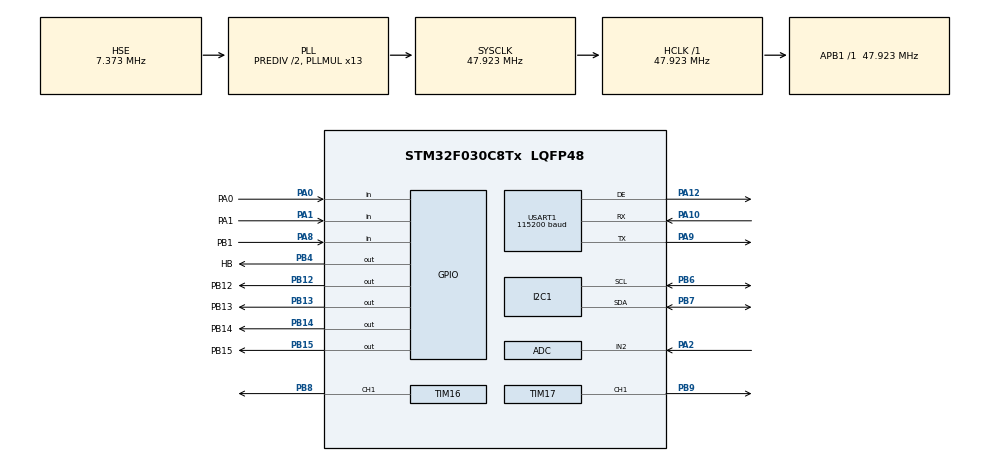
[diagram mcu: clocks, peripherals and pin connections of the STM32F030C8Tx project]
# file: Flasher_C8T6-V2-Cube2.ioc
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ADC.DMAContinuousRequests=ENABLE
ADC.EOCSelection=ADC_EOC_SEQ_CONV
ADC.ExternalTrigConv=ADC_EXTERNALTRIGCONV_T15_TRGO
ADC.SamplingTime=ADC_SAMPLETIME_13CYCLES_5
CRC.DefaultInitValueUse=DEFAULT_INIT_VALUE_ENABLE
Dma.ADC.4.Direction=DMA_PERIPH_TO_MEMORY
Dma.ADC.4.Instance=DMA1_Channel1
Dma.ADC.4.MemDataAlignment=DMA_MDATAALIGN_HALFWORD
Dma.ADC.4.MemInc=DMA_MINC_ENABLE
Dma.ADC.4.Mode=DMA_NORMAL
Dma.ADC.4.PeriphDataAlignment=DMA_PDATAALIGN_HALFWORD
Dma.ADC.4.PeriphInc=DMA_PINC_DISABLE
Dma.ADC.4.Priority=DMA_PRIORITY_LOW
Dma.I2C1_RX.0.Direction=DMA_PERIPH_TO_MEMORY
Dma.I2C1_RX.0.Instance=DMA1_Channel3
Dma.I2C1_RX.0.MemDataAlignment=DMA_MDATAALIGN_BYTE
Dma.I2C1_RX.0.MemInc=DMA_MINC_ENABLE
Dma.I2C1_RX.0.Mode=DMA_NORMAL
Dma.I2C1_RX.0.PeriphDataAlignment=DMA_PDATAALIGN_BYTE
Dma.I2C1_RX.0.PeriphInc=DMA_PINC_DISABLE
Dma.I2C1_RX.0.Priority=DMA_PRIORITY_LOW
Dma.I2C1_TX.1.Direction=DMA_MEMORY_TO_PERIPH
Dma.I2C1_TX.1.Instance=DMA1_Channel2
Dma.I2C1_TX.1.MemDataAlignment=DMA_MDATAALIGN_BYTE
Dma.I2C1_TX.1.MemInc=DMA_MINC_ENABLE
Dma.I2C1_TX.1.Mode=DMA_NORMAL
Dma.I2C1_TX.1.PeriphDataAlignment=DMA_PDATAALIGN_BYTE
Dma.I2C1_TX.1.PeriphInc=DMA_PINC_DISABLE
Dma.I2C1_TX.1.Priority=DMA_PRIORITY_LOW
Dma.Request0=I2C1_RX
Dma.Request1=I2C1_TX
Dma.Request2=USART1_TX
Dma.Request3=USART1_RX
Dma.Request4=ADC
Dma.USART1_RX.3.Direction=DMA_PERIPH_TO_MEMORY
Dma.USART1_RX.3.Instance=DMA1_Channel5
Dma.USART1_RX.3.MemDataAlignment=DMA_MDATAALIGN_BYTE
Dma.USART1_RX.3.MemInc=DMA_MINC_ENABLE
Dma.USART1_RX.3.Mode=DMA_CIRCULAR
Dma.USART1_RX.3.PeriphDataAlignment=DMA_PDATAALIGN_BYTE
Dma.USART1_RX.3.PeriphInc=DMA_PINC_DISABLE
Dma.USART1_RX.3.Priority=DMA_PRIORITY_LOW
Dma.USART1_TX.2.Direction=DMA_MEMORY_TO_PERIPH
Dma.USART1_TX.2.Instance=DMA1_Channel4
Dma.USART1_TX.2.MemDataAlignment=DMA_MDATAALIGN_BYTE
Dma.USART1_TX.2.MemInc=DMA_MINC_ENABLE
Dma.USART1_TX.2.Mode=DMA_NORMAL
Dma.USART1_TX.2.PeriphDataAlignment=DMA_PDATAALIGN_BYTE
Dma.USART1_TX.2.PeriphInc=DMA_PINC_DISABLE
Dma.USART1_TX.2.Priority=DMA_PRIORITY_LOW
I2C1.Timing=0x10805D87
Mcu.Family=STM32F0
Mcu.Name=STM32F030C8Tx
Mcu.Package=LQFP48
NVIC.DMA1_Channel1_IRQn=true\:0\:0\:false\:false\:true\:false\:true\:true
NVIC.DMA1_Channel2_3_IRQn=true\:0\:0\:false\:false\:true\:false\:true\:true
NVIC.DMA1_Channel4_5_IRQn=true\:0\:0\:false\:false\:true\:false\:true\:true
NVIC.I2C1_IRQn=true\:0\:0\:false\:false\:true\:true\:true\:true
NVIC.TIM16_IRQn=true\:0\:0\:false\:false\:true\:true\:true\:true
NVIC.TIM17_IRQn=true\:0\:0\:false\:false\:true\:true\:true\:true
NVIC.USART1_IRQn=true\:0\:0\:false\:false\:true\:true\:true\:true
PA0.GPIO_Label=PA0
PA0.GPIO_PuPd=GPIO_PULLUP
PA0.Signal=GPIO_Input
PA1.GPIO_Label=PA1
PA1.GPIO_PuPd=GPIO_PULLUP
PA1.Signal=GPIO_Input
PA10.Mode=Asynchronous
PA10.Signal=USART1_RX
PA12.Mode=Hardware Flow Control (RS485)
PA12.Signal=USART1_DE
PA13.Mode=Serial_Wire
PA13.Signal=SYS_SWDIO
PA14.Mode=Serial_Wire
PA14.Signal=SYS_SWCLK
PA2.Mode=IN2
PA2.Signal=ADC_IN2
PA8.GPIO_Label=PB1
PA8.GPIO_PuPd=GPIO_PULLUP
PA8.Signal=GPIO_Input
PA9.Mode=Asynchronous
PA9.Signal=USART1_TX
PB12.GPIO_Label=PB12
PB12.GPIO_Speed=GPIO_SPEED_FREQ_HIGH
PB12.Signal=GPIO_Output
PB13.GPIO_Label=PB13
PB13.GPIO_Speed=GPIO_SPEED_FREQ_HIGH
PB13.Signal=GPIO_Output
PB14.GPIO_Label=PB14
PB14.GPIO_Speed=GPIO_SPEED_FREQ_HIGH
PB14.Signal=GPIO_Output
PB15.GPIO_Label=PB15
PB15.GPIO_Speed=GPIO_SPEED_FREQ_HIGH
PB15.Signal=GPIO_Output
PB4.GPIO_Label=HB
PB4.Signal=GPIO_Output
PB6.Mode=I2C
PB6.Signal=I2C1_SCL
PB7.Mode=I2C
PB7.Signal=I2C1_SDA
PB8.GPIO_FM8=SYSCFG_CFGR1_I2C_FMP_PB8
PB8.GPIO_Speed=GPIO_SPEED_FREQ_HIGH
PB8.Signal=S_TIM16_CH1
PB9.GPIO_FM9=SYSCFG_CFGR1_I2C_FMP_PB9
PB9.GPIO_Speed=GPIO_SPEED_FREQ_HIGH
PB9.Signal=S_TIM17_CH1
PF0-OSC_IN.Mode=HSE-External-Oscillator
PF0-OSC_IN.Signal=RCC_OSC_IN
PF1-OSC_OUT.Mode=HSE-External-Oscillator
PF1-OSC_OUT.Signal=RCC_OSC_OUT
ProjectManager.HeapSize=0x200
ProjectManager.StackSize=0x400
ProjectManager.TargetToolchain=STM32CubeIDE
RCC.AHBFreq_Value=47923200
RCC.APB1Freq_Value=47923200
RCC.APB1TimFreq_Value=47923200
RCC.HCLKFreq_Value=47923200
RCC.HSE_VALUE=7372800
RCC.I2c1ClockSelection=RCC_I2C1CLKSOURCE_SYSCLK
RCC.PLLDivider=RCC_PREDIV_DIV2
RCC.PLLMUL=RCC_PLL_MUL13
RCC.PLLSourceVirtual=RCC_PLLSOURCE_HSE
RCC.SYSCLKFreq_VALUE=47923200
RCC.SYSCLKSource=RCC_SYSCLKSOURCE_PLLCLK
SH.S_TIM16_CH1.0=TIM16_CH1,PWM Generation1 CH1
SH.S_TIM17_CH1.0=TIM17_CH1,PWM Generation1 CH1
TIM15.AutoReloadPreload=TIM_AUTORELOAD_PRELOAD_ENABLE
TIM15.Period=207
TIM15.Prescaler=35
TIM15.TIM_MasterOutputTrigger=TIM_TRGO_UPDATE
TIM15.TIM_MasterSlaveMode=TIM_MASTERSLAVEMODE_DISABLE
TIM16.Channel=TIM_CHANNEL_1
TIM16.OCIdleState_1=TIM_OCIDLESTATE_SET
TIM16.OCPolarity_1=TIM_OCPOLARITY_LOW
TIM16.Period=32512
TIM16.Prescaler=20
TIM17.Channel=TIM_CHANNEL_1
TIM17.OCIdleState_1=TIM_OCIDLESTATE_SET
TIM17.OCPolarity_1=TIM_OCPOLARITY_LOW
TIM17.Period=32512
TIM17.Prescaler=20
USART1.BaudRate=115200
USART1.DMADisableonRxErrorParam=ADVFEATURE_DMA_ENABLEONRXERROR
USART1.OverrunDisableParam=ADVFEATURE_OVERRUN_ENABLE
USART1.StopBits=STOPBITS_1
USART1.VirtualMode-Asynchronous=VM_ASYNC
USART1.VirtualMode-Hardware\ Flow\ Control\ (RS485)=VM_ASYNC
VP_CRC_VS_CRC.Mode=CRC_Activate
VP_TIM14_VS_ClockSourceINT.Mode=Enable_Timer
VP_TIM15_VS_ClockSourceINT.Mode=Internal
VP_TIM16_VS_ClockSourceINT.Mode=Enable_Timer
VP_TIM17_VS_ClockSourceINT.Mode=Enable_Timer
VP_TIM3_VS_ClockSourceINT.Mode=Internal
board=custom

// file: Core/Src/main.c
/* USER CODE BEGIN Header */
/**
  ******************************************************************************
  * @file           : main.c
  * @brief          : Main program body
  ******************************************************************************
  * @attention
  *
  * Copyright (c) 2026 STMicroelectronics.
  * All rights reserved.
  *
  * This software is licensed under terms that can be found in the LICENSE file
  * in the root directory of this software component.
  * If no LICENSE file comes with this software, it is provided AS-IS.
  *
  ******************************************************************************
  */
/* USER CODE END Header */
#include "main.h"
#include "adc.h"
#include "crc.h"
#include "dma.h"
#include "i2c.h"
#include "tim.h"
#include "usart.h"
#include "gpio.h"

void SystemClock_Config(void);

int main(void)
{

  /* MCU Configuration--------------------------------------------------------*/

  /* Reset of all peripherals, Initializes the Flash interface and the Systick. */
  HAL_Init();

  /* Configure the system clock */
  SystemClock_Config();

  /* Initialize all configured peripherals */
  MX_GPIO_Init();
  MX_DMA_Init();
  MX_CRC_Init();
  MX_I2C1_Init();
  MX_TIM16_Init();
  MX_TIM17_Init();
  MX_USART1_UART_Init();
  MX_ADC_Init();
  MX_TIM14_Init();
  MX_TIM3_Init();
  MX_TIM15_Init();
  /* USER CODE BEGIN 2 */
  HAL_TIM_Base_Start(&htim14);
  HAL_TIM_Base_Start(&htim15);
  extern void TasksRun(void);
  TasksRun();
  /* USER CODE END 2 */

  /* Infinite loop */
  while (1)
  {

  }
}

void SystemClock_Config(void)
{
  RCC_OscInitTypeDef RCC_OscInitStruct = {0};
  RCC_ClkInitTypeDef RCC_ClkInitStruct = {0};
  RCC_PeriphCLKInitTypeDef PeriphClkInit = {0};

  /** Initializes the RCC Oscillators according to the specified parameters
  * in the RCC_OscInitTypeDef structure.
  */
  RCC_OscInitStruct.OscillatorType = RCC_OSCILLATORTYPE_HSI14|RCC_OSCILLATORTYPE_HSE;
  RCC_OscInitStruct.HSEState = RCC_HSE_ON;
  RCC_OscInitStruct.HSI14State = RCC_HSI14_ON;
  RCC_OscInitStruct.HSI14CalibrationValue = 16;
  RCC_OscInitStruct.PLL.PLLState = RCC_PLL_ON;
  RCC_OscInitStruct.PLL.PLLSource = RCC_PLLSOURCE_HSE;
  RCC_OscInitStruct.PLL.PLLMUL = RCC_PLL_MUL13;
  RCC_OscInitStruct.PLL.PREDIV = RCC_PREDIV_DIV2;
  if (HAL_RCC_OscConfig(&RCC_OscInitStruct) != HAL_OK)
  {
    Error_Handler();
  }

  /** Initializes the CPU, AHB and APB buses clocks
  */
  RCC_ClkInitStruct.ClockType = RCC_CLOCKTYPE_HCLK|RCC_CLOCKTYPE_SYSCLK
                              |RCC_CLOCKTYPE_PCLK1;
  RCC_ClkInitStruct.SYSCLKSource = RCC_SYSCLKSOURCE_PLLCLK;
  RCC_ClkInitStruct.AHBCLKDivider = RCC_SYSCLK_DIV1;
  RCC_ClkInitStruct.APB1CLKDivider = RCC_HCLK_DIV1;

  if (HAL_RCC_ClockConfig(&RCC_ClkInitStruct, FLASH_LATENCY_1) != HAL_OK)
  {
    Error_Handler();
  }
  PeriphClkInit.PeriphClockSelection = RCC_PERIPHCLK_USART1|RCC_PERIPHCLK_I2C1;
  PeriphClkInit.Usart1ClockSelection = RCC_USART1CLKSOURCE_PCLK1;
  PeriphClkInit.I2c1ClockSelection = RCC_I2C1CLKSOURCE_SYSCLK;
  if (HAL_RCCEx_PeriphCLKConfig(&PeriphClkInit) != HAL_OK)
  {
    Error_Handler();
  }
}

void Error_Handler(void)
{
  __disable_irq();
  while (1)
  {
  }
}
